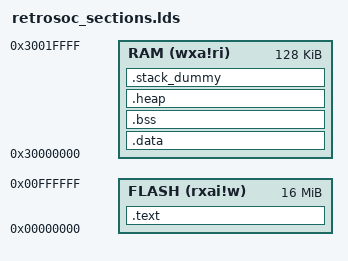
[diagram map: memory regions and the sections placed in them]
MEMORY
{
    FLASH (rxai!w) : ORIGIN = 0x00000000, LENGTH = 16M
    RAM (wxa!ri) : ORIGIN = 0x30000000, LENGTH = 128K
}
SECTIONS {
    .text :
    {
        . = ALIGN(4);
        *(.text)
        *(.text*)
        *(.rodata)
        *(.rodata*)
        *(.srodata)
        *(.srodata*)
        . = ALIGN(4);
        _etext = .;
        _sidata = _etext;
    } >FLASH
    .data : AT ( _sidata )
    {
        . = ALIGN(4);
        _sdata = .;
        _ram_start = .;
        . = ALIGN(4);
        *(.data)
        *(.data*)
        *(.sdata)
        *(.sdata*)
        . = ALIGN(4);
        _edata = .;
    } >RAM
    .bss :
    {
        . = ALIGN(4);
        _sbss = .;
        *(.bss)
        *(.bss*)
        *(.sbss)
        *(.sbss*)
        *(COMMON)
        . = ALIGN(4);
        _ebss = .;
    } >RAM
    .heap :
    {
        . = ALIGN(4);
        _heap_start = .;
    } >RAM
    .stack_dummy ORIGIN(RAM) + LENGTH(RAM) :
    {
        PROVIDE( _stack_point = . );
    } >RAM
}
